# STM32L4A6 register map
File version: 1.0
CPU: CM4 r0p1, little endian, MPU, FPU, 4 interrupt priority bits
Registers are 32-bit, read-write, reset 0x0 unless marked. A register's access mark holds for its fields unless they carry their own. Offsets are from the block's base; [hi:lo] are bit positions; {n}, {i} and the like mark numbered series; 'fields as' and 'values as' point back to an identical list.

## FMC — Flexible memory controller
Base 0xA0000000
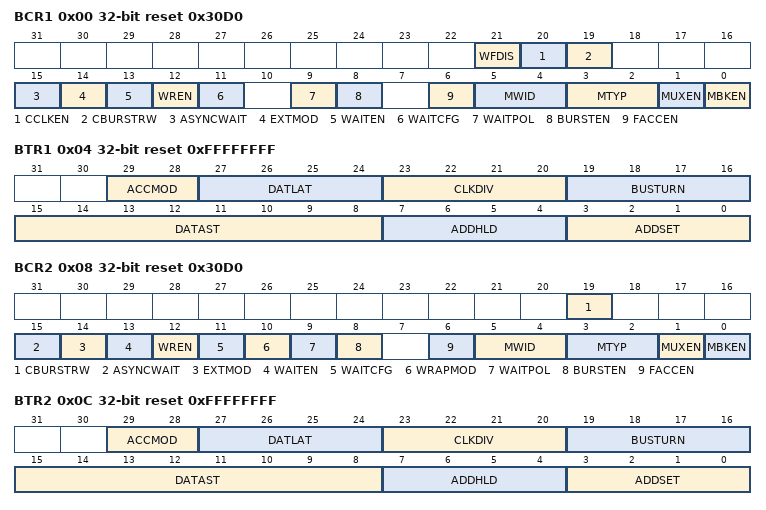
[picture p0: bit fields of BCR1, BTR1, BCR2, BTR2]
0x00 BCR1 reset 0x30D0 — SRAM/NOR-Flash chip-select control register 1
  [21] WFDIS — Write FIFO Disable
  [20] CCLKEN
  [19] CBURSTRW
  [15] ASYNCWAIT
  [14] EXTMOD
  [13] WAITEN
  [12] WREN
  [11] WAITCFG
  [9] WAITPOL
  [8] BURSTEN
  [6] FACCEN
  [5:4] MWID
  [3:2] MTYP
  [1] MUXEN
  [0] MBKEN
0x04 BTR1 reset 0xFFFFFFFF — SRAM/NOR-Flash chip-select timing register 1
  [29:28] ACCMOD, [27:24] DATLAT, [23:20] CLKDIV, [19:16] BUSTURN, [15:8] DATAST, [7:4] ADDHLD, [3:0] ADDSET
0x08 BCR2 reset 0x30D0 — SRAM/NOR-Flash chip-select control register 2
  [19] CBURSTRW, [15] ASYNCWAIT, [14] EXTMOD, [13] WAITEN, [12] WREN, [11] WAITCFG, [10] WRAPMOD, [9] WAITPOL, [8] BURSTEN, [6] FACCEN, [5:4] MWID, [3:2] MTYP, [1] MUXEN, [0] MBKEN
0x0C BTR2 reset 0xFFFFFFFF — SRAM/NOR-Flash chip-select timing register 2
  fields as BTR1
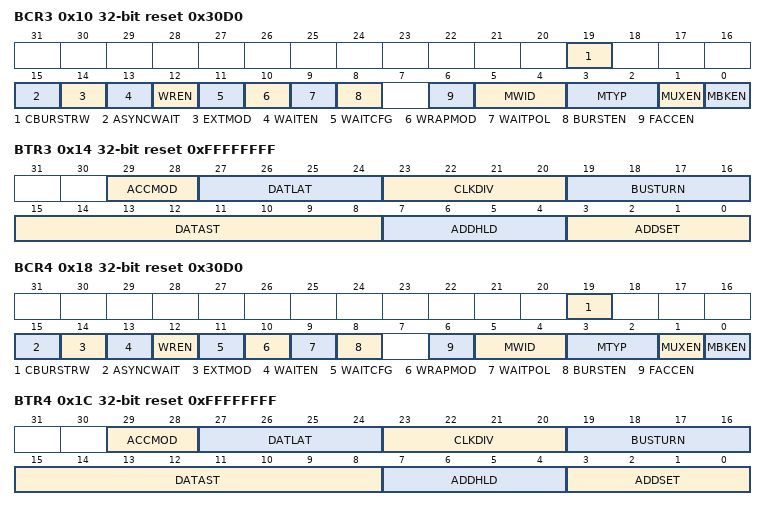
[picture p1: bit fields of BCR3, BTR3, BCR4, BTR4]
0x10 BCR3 reset 0x30D0 — SRAM/NOR-Flash chip-select control register 3
  fields as BCR2
0x14 BTR3 reset 0xFFFFFFFF — SRAM/NOR-Flash chip-select timing register 3
  fields as BTR1
0x18 BCR4 reset 0x30D0 — SRAM/NOR-Flash chip-select control register 4
  fields as BCR2
0x1C BTR4 reset 0xFFFFFFFF — SRAM/NOR-Flash chip-select timing register 4
  fields as BTR1
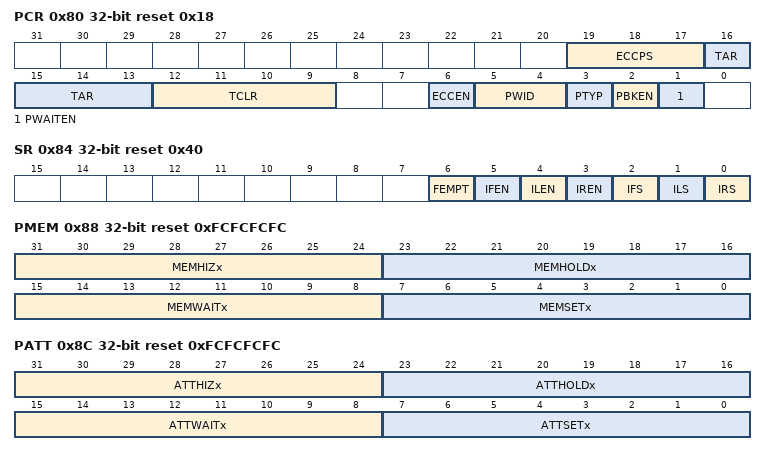
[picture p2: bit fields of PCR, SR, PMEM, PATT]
0x80 PCR reset 0x18 — PC Card/NAND Flash control register 3
  [19:17] ECCPS, [16:13] TAR, [12:9] TCLR, [6] ECCEN, [5:4] PWID, [3] PTYP, [2] PBKEN, [1] PWAITEN
0x84 SR access per field reset 0x40 — FIFO status and interrupt register 3
  [6] FEMPT ro, [5] IFEN rw, [4] ILEN rw, [3] IREN rw, [2] IFS rw, [1] ILS rw, [0] IRS rw
0x88 PMEM reset 0xFCFCFCFC — Common memory space timing register 3
  [31:24] MEMHIZx, [23:16] MEMHOLDx, [15:8] MEMWAITx, [7:0] MEMSETx
0x8C PATT reset 0xFCFCFCFC — Attribute memory space timing register 3
  [31:24] ATTHIZx, [23:16] ATTHOLDx, [15:8] ATTWAITx, [7:0] ATTSETx
0x94 ECCR ro — ECC result register 3
  [31:0] ECCx
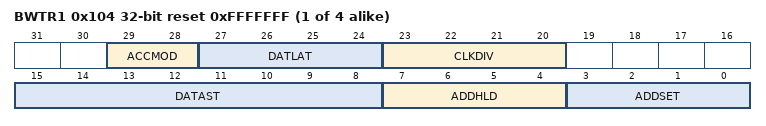
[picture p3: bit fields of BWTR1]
{0xFC+8i} BWTR{i} reset 0xFFFFFFF (i=1..4) — SRAM/NOR-Flash write timing registers {i}
  [29:28] ACCMOD, [27:24] DATLAT, [23:20] CLKDIV, [15:8] DATAST, [7:4] ADDHLD, [3:0] ADDSET

## CRS — Clock recovery system
Base 0x40006000
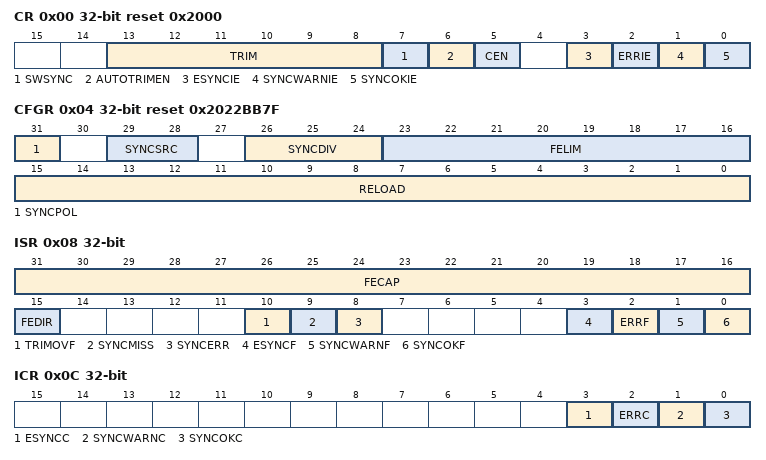
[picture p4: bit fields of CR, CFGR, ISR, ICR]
0x00 CR reset 0x2000 — control register
  [13:8] TRIM — HSI48 oscillator smooth trimming
  [7] SWSYNC — Generate software SYNC event
  [6] AUTOTRIMEN — Automatic trimming enable
  [5] CEN — Frequency error counter enable
  [3] ESYNCIE — Expected SYNC interrupt enable
  [2] ERRIE — Synchronization or trimming error interrupt enable
  [1] SYNCWARNIE — SYNC warning interrupt enable
  [0] SYNCOKIE — SYNC event OK interrupt enable
0x04 CFGR reset 0x2022BB7F — configuration register
  [31] SYNCPOL — SYNC polarity selection
  [29:28] SYNCSRC — SYNC signal source selection
  [26:24] SYNCDIV — SYNC divider
  [23:16] FELIM — Frequency error limit
  [15:0] RELOAD — Counter reload value
0x08 ISR ro — interrupt and status register
  [31:16] FECAP — Frequency error capture
  [15] FEDIR — Frequency error direction
  [10] TRIMOVF — Trimming overflow or underflow
  [9] SYNCMISS — SYNC missed
  [8] SYNCERR — SYNC error
  [3] ESYNCF — Expected SYNC flag
  [2] ERRF — Error flag
  [1] SYNCWARNF — SYNC warning flag
  [0] SYNCOKF — SYNC event OK flag
0x0C ICR — interrupt flag clear register
  [3] ESYNCC — Expected SYNC clear flag
  [2] ERRC — Error clear flag
  [1] SYNCWARNC — SYNC warning clear flag
  [0] SYNCOKC — SYNC event OK clear flag

## DCMI — Digital camera interface
Base 0x50050000
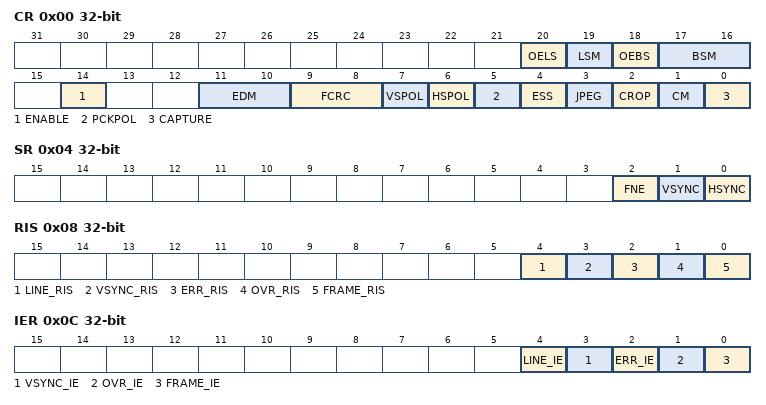
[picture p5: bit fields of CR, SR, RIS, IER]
0x00 CR — control register 1
  [20] OELS — Odd/Even Line Select (Line Select Start)
  [19] LSM — Line Select mode
  [18] OEBS — Odd/Even Byte Select (Byte Select Start)
  [17:16] BSM — Byte Select mode
  [14] ENABLE — DCMI enable
  [11:10] EDM — Extended data mode
  [9:8] FCRC — Frame capture rate control
  [7] VSPOL — Vertical synchronization polarity
  [6] HSPOL — Horizontal synchronization polarity
  [5] PCKPOL — Pixel clock polarity
  [4] ESS — Embedded synchronization select
  [3] JPEG — JPEG format
  [2] CROP — Crop feature
  [1] CM — Capture mode
  [0] CAPTURE — Capture enable
0x04 SR ro — status register
  [2] FNE — FIFO not empty
  [1] VSYNC
  [0] HSYNC
0x08 RIS ro — raw interrupt status register
  [4] LINE_RIS — Line raw interrupt status
  [3] VSYNC_RIS — VSYNC raw interrupt status
  [2] ERR_RIS — Synchronization error raw interrupt status
  [1] OVR_RIS — Overrun raw interrupt status
  [0] FRAME_RIS — Capture complete raw interrupt status
0x0C IER — interrupt enable register
  [4] LINE_IE — Line interrupt enable
  [3] VSYNC_IE — VSYNC interrupt enable
  [2] ERR_IE — Synchronization error interrupt enable
  [1] OVR_IE — Overrun interrupt enable
  [0] FRAME_IE — Capture complete interrupt enable
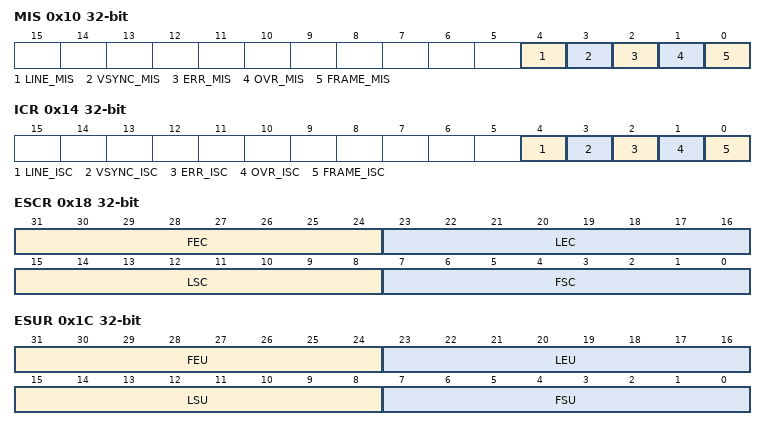
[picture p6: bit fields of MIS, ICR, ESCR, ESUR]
0x10 MIS ro — masked interrupt status register
  [4] LINE_MIS — Line masked interrupt status
  [3] VSYNC_MIS — VSYNC masked interrupt status
  [2] ERR_MIS — Synchronization error masked interrupt status
  [1] OVR_MIS — Overrun masked interrupt status
  [0] FRAME_MIS — Capture complete masked interrupt status
0x14 ICR wo — interrupt clear register
  [4] LINE_ISC — line interrupt status clear
  [3] VSYNC_ISC — Vertical synch interrupt status clear
  [2] ERR_ISC — Synchronization error interrupt status clear
  [1] OVR_ISC — Overrun interrupt status clear
  [0] FRAME_ISC — Capture complete interrupt status clear
0x18 ESCR — embedded synchronization code register
  [31:24] FEC — Frame end delimiter code
  [23:16] LEC — Line end delimiter code
  [15:8] LSC — Line start delimiter code
  [7:0] FSC — Frame start delimiter code
0x1C ESUR — embedded synchronization unmask register
  [31:24] FEU — Frame end delimiter unmask
  [23:16] LEU — Line end delimiter unmask
  [15:8] LSU — Line start delimiter unmask
  [7:0] FSU — Frame start delimiter unmask
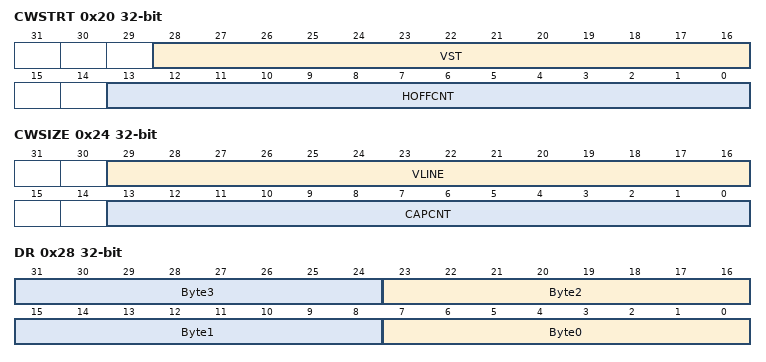
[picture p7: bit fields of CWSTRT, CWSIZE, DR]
0x20 CWSTRT — crop window start
  [28:16] VST — Vertical start line count
  [13:0] HOFFCNT — Horizontal offset count
0x24 CWSIZE — crop window size
  [29:16] VLINE — Vertical line count
  [13:0] CAPCNT — Capture count
0x28 DR ro — data register
  [8n+7:8n] Byte{n} (n=0..3) — Data byte {n}
